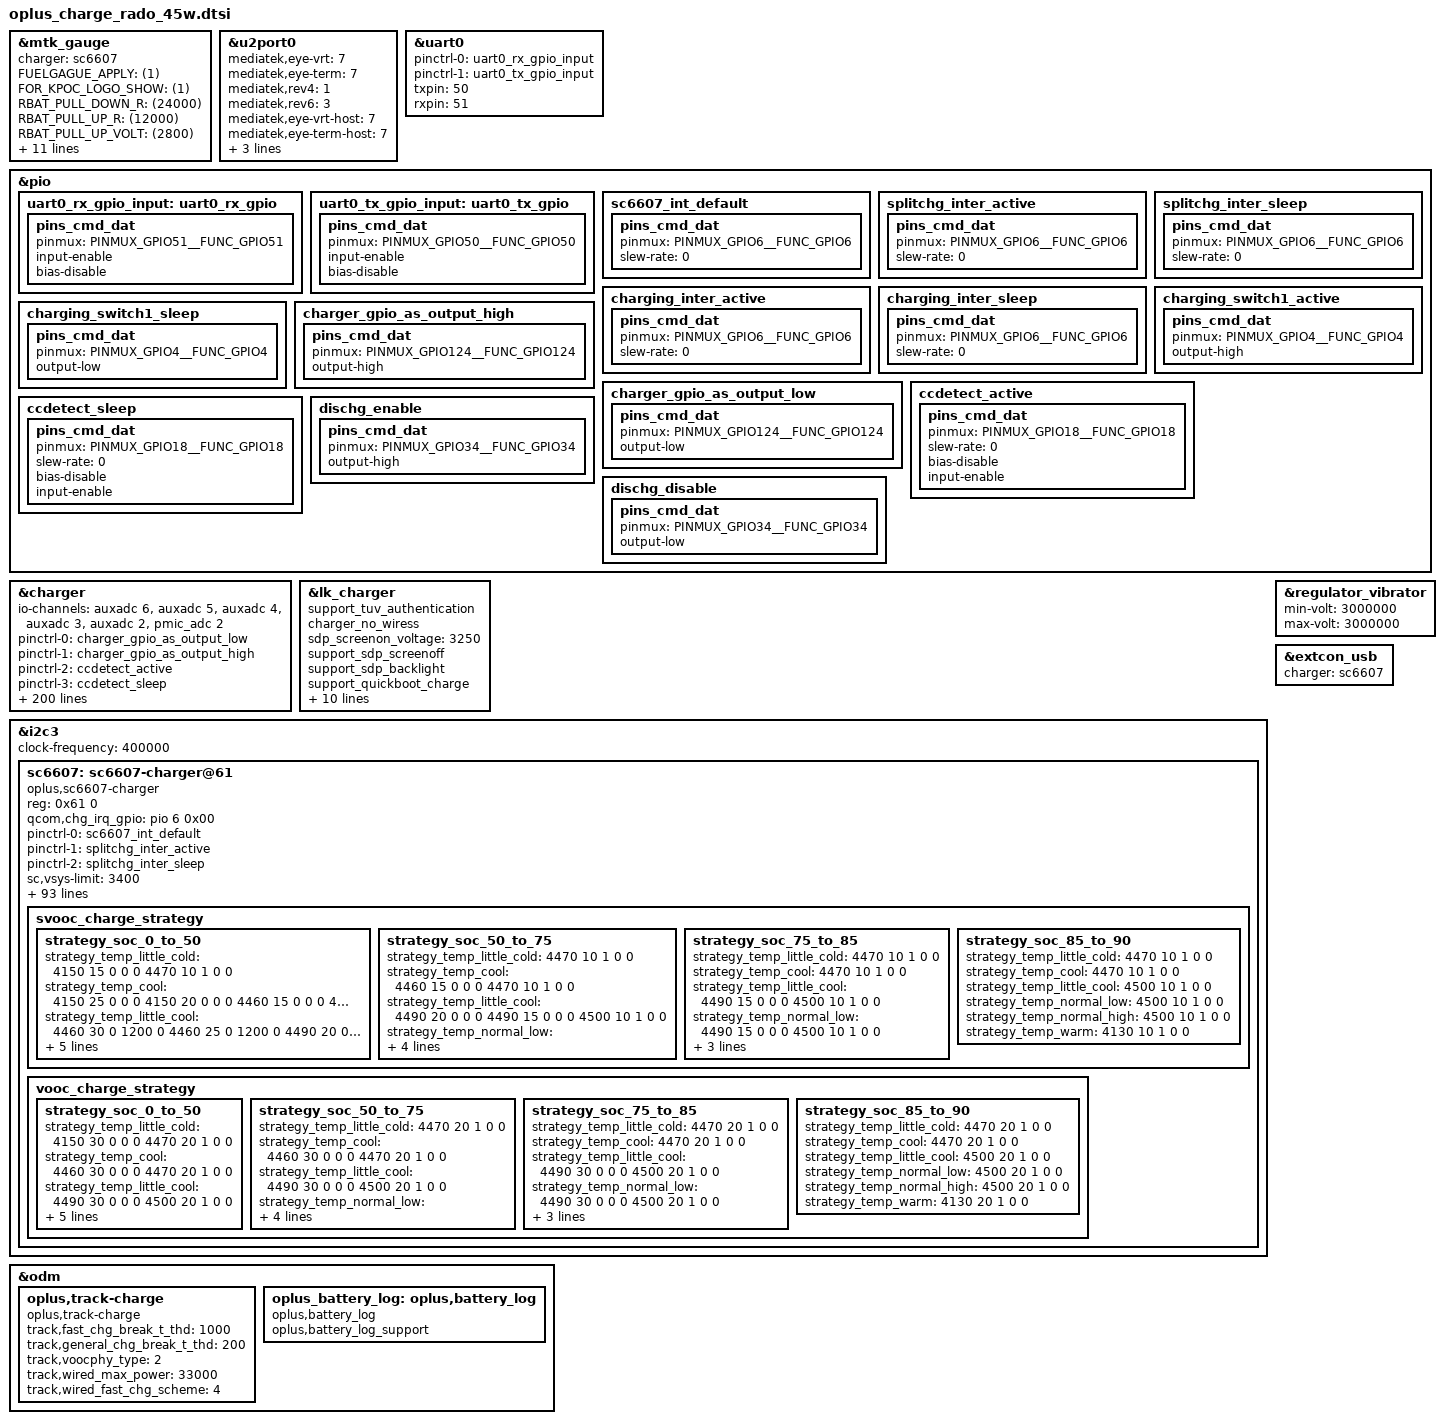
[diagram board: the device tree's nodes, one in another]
// SPDX-License-Identifier: GPL-2.0-only
/*
* Copyright (C) 2021-2020 Oplus. All rights reserved.
*/

/*
 *
 * CPU:MT6835 Barley
 * UTXD0 -->GPIO50
 * URXD0 -->GPIO51
 * I2C
 * MASTER_CHG/CCLOGIC --> I2C5
 * IRQB
 * EINT_CHG_1 (cp1 irq)                -->GPIO6
 * EINT_CHG_2 (cp2 irq)                -->GPIO18
 * CC_CNTL_INT_N(cc login irq)          --> GPIO12
 * CHG_INT(main irq)           --> GPIO3
 *
 * GPIO
 * MAIN/CCLOGIN_SCL               --> GPIO137(SCL5)
 * MAIN/CCLOGIN_SDA               --> GPIO138(SDA5)
 * USB_SWITCH_2(uart/vooc switch)      --> GPIO4
 * VBUS_SHORT(防烧口)           --> GPIO34
 * CHARGER_PUMP1_SCL               --> GPIO133(CP1_SCL3)
 * CHARGER_PUMP1_SDA               --> GPIO134(CP1_SDA3)
 * CHARGER_PUMP2_SCL               --> GPIO141(CP2_SCL7)
 * CHARGER_PUMP2_SDA               --> GPIO142(CP2_SDA7)
 * USB_SWITCH_1(usb/uart&vooc switch)    --> GPIO124
 * SEC_IC (加密电池GPIO for 67W)    --> GPIO44
 *
 * AP_AUXADC:
 * 0				--> FLASH_LED1_NTC
 * 1				--> NTC_USBCON_TEM (BTB VBUS旁)
 * 2				--> NTC_CHARGE (充电IC旁)
 * 3				--> USB_TEM2_ADC (BB_USB_ADC2 r/l?)
 * 4				--> USB_TEM1_ADC (BB_USB_ADC1)
 * 5				--> BAT_ID_ADC   (battery id)
 * 6				--> NTC_charging （BTB电池座子旁）
 */


#include <dt-bindings/iio/mt635x-auxadc.h>
#include <dt-bindings/pinctrl/mt6373-pinfunc.h>
#include <dt-bindings/pinctrl/mt65xx.h>
#include "oplus_chg.h"
/* charge start */

&mtk_gauge {
	status = "okay";
	charger = <&sc6607>;
	FUELGAGUE_APPLY = <(1)>;
	FOR_KPOC_LOGO_SHOW = <(1)>;
	RBAT_PULL_DOWN_R = <(24000)>;
	RBAT_PULL_UP_R = <(12000)>;
	RBAT_PULL_UP_VOLT = <(2800)>;
	USE_MORE_PRECISE_NTC_TABLE = <(1)>;
	//NTC_SERIES_R = <(5100)>;
	FG_METER_RESISTANCE = <(45)>; /* The resistance of PCB */
	CAR_TUNE_VALUE = <(99)>; /* Tune value for current measurement */
	BATT_ID_FAST_CHECK = <(1)>;
	R_FG_VALUE = <(2)>;/* R_sense resistance */
	io-channels = <&pmic_adc AUXADC_BAT_TEMP>,
				<&pmic_adc AUXADC_BATADC>,
				<&pmic_adc AUXADC_VBIF>,
				<&pmic_adc AUXADC_IMP>,
				<&pmic_adc AUXADC_IMIX_R>,
				<&auxadc 5>;
	io-channel-names = "pmic_battery_temp",
					"pmic_battery_voltage",
					"pmic_bif_voltage",
					"pmic_ptim_voltage",
					"pmic_ptim_r",
					 "auxadc5-batt_id_v";


    //IS_SUBBOARD_TEMP_SUPPORT = <(1)>;
	Enable_Is_Force_Full = <(1)>;
	DIM2_TABLE_DISTINGUISH = <(1)>;
	#include "mediatek/bat_setting/mt6835_rado_battery_table_45w.dtsi"
	#include "mediatek/bat_setting/mt6835_rado_battery_prop_dim2_ext_45w.dtsi"
};

&u2port0 {
    mediatek,eye-vrt = <7>;
    mediatek,eye-term = <7>;
    mediatek,rev4 = <1>;
    mediatek,rev6 = <3>;
    mediatek,eye-vrt-host = <7>;
    mediatek,eye-term-host = <7>;
    mediatek,rev6-host = <3>;
    mediatek,discth = <10>;
    mediatek,rx-sqth = <5>;
};


&uart0 {
	pinctrl-names = "uart0_rx_gpio", "uart0_tx_gpio";
	pinctrl-0 = <&uart0_rx_gpio_input>;
	pinctrl-1 = <&uart0_tx_gpio_input>;
	status = "okay";

	txpin = <50>;
	rxpin = <51>;
};

&pio {
	uart0_rx_gpio_input: uart0_rx_gpio {
		pins_cmd_dat {
			pinmux = <PINMUX_GPIO51__FUNC_GPIO51>;
			input-enable;
			bias-disable;
		};
	};

	uart0_tx_gpio_input: uart0_tx_gpio {
		pins_cmd_dat {
			pinmux = <PINMUX_GPIO50__FUNC_GPIO50>;
			input-enable;
			bias-disable;
		};
	};
};


&charger {
	io-channels = <&auxadc 6>,<&auxadc 5>,<&auxadc 4>,<&auxadc 3>,<&auxadc 2>,<&pmic_adc 2>;
	io-channel-names = "auxadc6_batt_btb_temp","auxadc5temp","usb_temp_v_l","usb_temp_v_r","auxadc2-chargeric_temp","pmic_vcdt_voltage";

	pinctrl-names = "charger_gpio_as_output_low","charger_gpio_as_output_high",
					"ccdetect_active","ccdetect_sleep","dischg_enable","dischg_disable";
	pinctrl-0 = <&charger_gpio_as_output_low>;
	pinctrl-1 = <&charger_gpio_as_output_high>;
	pinctrl-2 = <&ccdetect_active>;
	pinctrl-3 = <&ccdetect_sleep>;
	pinctrl-4 = <&dischg_enable>;
	pinctrl-5 = <&dischg_disable>;

	gauge = <&mtk_gauge>;
	charger = <&sc6607>;

	//for oplus chg framework:
	qcom,pps_support_type = <0>;
	qcom,pd_input_current_charger_ma = <2000>;
	qcom,qc_input_current_charger_ma = <2000>;
	qcom,input_current_charger_ma = <2000>;
	qcom,input_current_usb_ma = <500>;
	qcom,input_current_cdp_ma = <1500>;
	qcom,input_current_camera_ma = <1200>;
	qcom,input_current_calling_ma = <1500>;

	qcom,led_warm_bat_decidegc = <350>;
	qcom,led_high_bat_decidegc = <370>;
	qcom,input_current_led_ma = <1200>;
	qcom,input_current_led_ma_high = <1200>;
	qcom,input_current_led_ma_warm = <1500>;
	qcom,input_current_led_ma_normal = <3000>;
	qcom,input_current_led_ma_forcmcc = <500>;
	qcom,input_current_led_ma_limit_high = <1200>;

	qcom,vooc_temp_bat_normal_decidegc = <350>;
	qcom,vooc_temp_bat_warm_decidegc = <370>;
	qcom,vooc_temp_bat_hot_decidegc = <440>;
	qcom,input_current_vooc_led_ma_high = <1200>;
	qcom,input_current_vooc_led_ma_warm = <1800>;
	qcom,input_current_vooc_led_ma_normal = <3600>;
	qcom,input_current_vooc_ma_normal = <3600>;
	qcom,input_current_vooc_ma_warm = <3200>;
	qcom,input_current_vooc_ma_high = <2200>;

	qcom,overtemp_bat_decidegc = <400>;
	qcom,iterm_disabled = <0>;
	//sw_full_count = <25>;
	qcom,iterm_ma = <290>;
	qcom,recharge-mv = <100>;

	qcom,batt_capacity_mah = <5600>; /*typical capacity*/
	qcom,usb_high_than_bat_decidegc = <168>;

	qcom,removed_bat_decidegc = <390>;  /* < -15C */

	qcom,cold_bat_decidegc = <100>;  /* -10C ~ 0C */
	qcom,temp_cold_vfloat_mv = <4465>;
	qcom,temp_cold_fastchg_current_ma_high = <1120>;
	qcom,temp_cold_fastchg_current_ma_low = <840>;
	qcom,temp_cold_fastchg_current_ma = <840>;

	qcom,little_cold_bat_decidegc = <0>;    /* 0C ~ 5C */
	qcom,temp_little_cold_vfloat_mv = <4465>;
	qcom,temp_little_cold_fastchg_current_ma_high = <2200>;
	qcom,temp_little_cold_fastchg_current_ma_low = <2200>;
	qcom,temp_little_cold_fastchg_current_ma = <2200>;
	qcom,qc_temp_little_cold_fastchg_current_ma_high = <3000>;
	qcom,qc_temp_little_cold_fastchg_current_ma_low = <2000>;
	qcom,pd_temp_little_cold_fastchg_current_ma_high = <3000>;
	qcom,pd_temp_little_cold_fastchg_current_ma_low = <2000>;

	qcom,cool_bat_decidegc = <50>;  /* 5C ~ 12C */
	qcom,temp_cool_vfloat_mv = <4465>;
	qcom,temp_cool_fastchg_current_ma_high = <2200>;
	qcom,temp_cool_fastchg_current_ma_low = <2200>;
	qcom,qc_temp_cool_fastchg_current_ma_high = <3000>;
	qcom,qc_temp_cool_fastchg_current_ma_low = <3000>;
	qcom,pd_temp_cool_fastchg_current_ma_high = <3000>;
	qcom,pd_temp_cool_fastchg_current_ma_low = <3000>;

	qcom,little_cool_bat_decidegc = <120>;  /* 12C ~ 16C */
	qcom,temp_little_cool_vfloat_mv = <4465>;
	qcom,temp_little_cool_fastchg_current_ma = <2200>;
	qcom,pd_temp_little_cool_fastchg_current_ma = <3000>;
	qcom,qc_temp_little_cool_fastchg_current_ma = <3000>;

	qcom,normal_bat_decidegc = <160>;       /* 16C ~ 45C */
	qcom,temp_normal_vfloat_mv = <4465>;
	qcom,temp_normal_fastchg_current_ma = <2200>;
	qcom,pd_temp_normal_fastchg_current_ma = <2000>;
	qcom,qc_temp_normal_fastchg_current_ma = <2000>;

	qcom,warm_bat_decidegc = <450>;         /* 45C ~ 53C */ /*8pin Bat Vooc project need add 3 degree C*/
	qcom,temp_warm_vfloat_mv = <4130>;
	qcom,temp_warm_fastchg_current_ma = <2200>;
	qcom,pd_temp_warm_fastchg_current_ma = <2000>;
	qcom,qc_temp_warm_fastchg_current_ma = <2000>;
	qcom,temp_warm_fastchg_current_ma_led_on = <1000>;

	qcom,hot_bat_decidegc = <530>;  /* > 53C */

	qcom,non_standard_vfloat_mv = <3980>;
	qcom,non_standard_fastchg_current_ma = <512>;

	qcom,short_c_bat_cv_mv = <4330>;
	qcom,short_c_bat_vfloat_mv = <3800>;
	qcom,short_c_bat_fastchg_current_ma = <512>;
	qcom,short_c_bat_vfloat_sw_limit = <3750>;

	qcom,cold_vfloat_sw_limit = <4415>;
	qcom,little_cold_vfloat_sw_limit = <4415>;
	qcom,cool_vfloat_sw_limit = <4415>;
	qcom,little_cool_vfloat_sw_limit = <4415>;
	qcom,normal_vfloat_sw_limit = <4415>;
	qcom,warm_vfloat_sw_limit = <4080>;
	qcom,non_standard_vfloat_sw_limit = <3930>;

	qcom,max_chg_time_sec = <72000>;
	qcom,charger_hv_thr = <10000>;
	qcom,charger_recv_thr = <9800>;
	qcom,charger_lv_thr = <3400>;
	qcom,vbatt_full_thr = <4465>;
	qcom,vbatt_hv_thr = <4600>;

	qcom,vfloat_step_mv = <16>;
	qcom,non_standard_vfloat_over_sw_limit = <3990>;
	qcom,cold_vfloat_over_sw_limit = <4445>;
	qcom,little_cold_vfloat_over_sw_limit = <4445>;
	qcom,cool_vfloat_over_sw_limit = <4445>;
	qcom,little_cool_vfloat_over_sw_limit = <4445>;
	qcom,normal_vfloat_over_sw_limit = <4440>;
	qcom,warm_vfloat_over_sw_limit = <4140>;

	qcom,vbatt_power_off = <3300>;
	qcom,vbatt_soc_1 = <3410>;
	qcom,vooc_project = <21>;
	qcom,vbatt_num = <1>;
	qcom,new_ui_warning_support;
	qcom,smart_charging_screenoff;
	qcom,smart_charge_version = <1>;

	qcom,normal_vterm_hw_inc = <18>;
	qcom,non_normal_vterm_hw_inc = <18>;
	qcom,usbtemp_batttemp_gap = <12>;

	qcom,ff1_normal_fastchg_ma = <1500>; /*12C~35c*/
	qcom,ff1_warm_fastchg_ma = <1500>;	/* 35C ~ 40c */
	qcom,ff1_exit_step_ma = <850>;
	qcom,ff1_warm_exit_step_ma = <900>;

	qcom,ffc2_normal_fastchg_ma = <900>;/*12C~35c*/
	qcom,ffc2_warm_fastchg_ma = <1000>;	/* 35C ~ 40c */
	qcom,ffc2_temp_warm_decidegc = <350>;
	qcom,ffc2_temp_high_decidegc = <430>;
	qcom,ffc2_temp_low_decidegc = <120>;
	qcom,ffc2_exit_step_ma = <850>;
	qcom,ffc2_warm_exit_step_ma = <900>;

	qcom,ffc_normal_vfloat_sw_limit = <4495>;
	qcom,ffc_temp_normal_vfloat_mv = <4580>;
	qcom,ffc_normal_vfloat_over_sw_limit = <4630>;
	qcom,ffc_warm_vfloat_sw_limit = <4495>;

	qcom,ffc2_normal_vfloat_sw_limit = <4495>;
	qcom,ffc2_temp_normal_vfloat_mv = <4580>;
	qcom,ffc2_normal_vfloat_over_sw_limit = <4630>;
	qcom,ffc2_warm_vfloat_sw_limit = <4495>;


	qcom,default_iterm_ma = <290>;
	qcom,default_temp_normal_fastchg_current_ma = <2200>;
	qcom,default_normal_vfloat_sw_limit = <4415>;
	qcom,default_temp_normal_vfloat_mv = <4465>;
	qcom,default_normal_vfloat_over_sw_limit = <4475>;

	qcom,default_temp_little_cool_fastchg_current_ma = <2200>;
	qcom,default_little_cool_vfloat_sw_limit = <4415>;
	qcom,default_temp_little_cool_vfloat_mv = <4465>;
	qcom,default_little_cool_vfloat_over_sw_limit = <4475>;

	//for PD9V or QC9V
	qcom,vbatt_pdqc_to_5v_thr = <4500>;
	qcom,vbatt_pdqc_to_9v_thr = <4500>;

	//for PD or QC control
	//qcom,qc_not_support;

	//for control:
	//qcom,suspend_after_full;
	qcom,support_abnormal_adapter;
	qcom,check_batt_full_by_sw;
	qcom,chg_ctrl_by_lcd;
	qcom,chg_ctrl_by_camera;
	qcom,chg_ctrl_by_calling;
	qcom,sw_vfloat_over_protect_enable;
	qcom,usbtemp_dischg_by_platpmic;
	//add for usb temp protect
	qcom,support_usbtemp_protect_v2;
	qcom,usbtemp_batt_temp_low = <50>;
	qcom,usbtemp_batt_temp_high = <50>;
	qcom,usbtemp_ntc_temp_low = <57>;
	qcom,usbtemp_ntc_temp_high = <69>;
	qcom,usbtemp_temp_gap_low_with_batt_temp = <7>;
	qcom,usbtemp_temp_gap_high_with_batt_temp = <12>;
	qcom,usbtemp_temp_gap_low_without_batt_temp = <12>;
	qcom,usbtemp_temp_gap_high_without_batt_temp = <24>;
	qcom.usbtemp_rise_fast_temp_low = <3>;
	qcom.usbtemp_rise_fast_temp_high = <3>;
	qcom.usbtemp_rise_fast_temp_count_low = <30>;
	qcom.usbtemp_rise_fast_temp_count_high = <20>;

	qcom,usbtemp_cool_down_ntc_low = <54>;
	qcom,usbtemp_cool_down_ntc_high = <65>;
	qcom,usbtemp_cool_down_gap_low = <12>;
	qcom,usbtemp_cool_down_gap_high = <20>;
	qcom,usbtemp_cool_down_recover_ntc_low = <48>;
	qcom,usbtemp_cool_down_recover_ntc_high = <60>;
	qcom,usbtemp_cool_down_recover_gap_low = <6>;
	qcom,usbtemp_cool_down_recover_gap_high = <15>;
	qcom,ffc_support;
	qcom,chargerid_vol_disable;
	qcom,support_ntc_01c_precision;
	qcom,voocphy_support = <2>;
	//qcom,external_authenticate;
	qcom,chargerid_support;
	qcom,vooc_show_ui_soc_decimal;
	qcom,ui_soc_decimal_speedmin = <20>;//2A
	//qcom,ccdetect_by_wd0;
	qcom,hvdcp_disabled; //do'not supprot hvdcp
	//GPIO config:
	qcom,chargerid_switch-gpio = <&pio 124 0x00>;/*USB_SWITCH_1*/
	qcom,dischg-gpio = <&pio 34 0x00>;/*VBUS_SHORT*/
	qcom,ccdetect-gpio = <&pio 18 0x00>;

	qcom,vooc-max-input-volt-support = <10000>;     //10V
	qcom,vooc-max-input-current-support = <3000>;   //3A

	oplus,uart_tx-gpio = <&pio 50 0x00>;
	oplus,uart_rx-gpio = <&pio 51 0x00>;
};

&lk_charger {
	support_tuv_authentication;
	charger_no_wiress;
	sdp_screenon_voltage = <3250>;
	//sub_board_temp_support;
	support_sdp_screenoff;
	support_sdp_backlight;
	support_quickboot_charge;
	support_4p48_single_battery;
	max_charger_voltage = <15000000>;
	boot_battery_voltage = <3400000>;
	usb_charger_current = <500000>;
	ac_charger_current = <2050000>;
	ac_charger_input_current = <1500000>;
	non_std_ac_charger_current = <750000>;
	charging_host_charger_current = <1500000>;
	ta_ac_charger_current = <1500000>;
	pd_charger_current = <500000>;
};

&i2c3 {
	status = "okay";
	clock-frequency = <400000>;//400K
	sc6607:sc6607-charger@61{
		status = "okay";
		compatible = "oplus,sc6607-charger";
		reg = <0x61 0>;

		qcom,chg_irq_gpio = <&pio 6 0x00>;
		pinctrl-names = "default",
				"splitchg_inter_active",
				"splitchg_inter_sleep";

		pinctrl-0 = <&sc6607_int_default>;
		pinctrl-1 = <&splitchg_inter_active>;
		pinctrl-2 = <&splitchg_inter_sleep>;
		sc,vsys-limit = <3400>;
		sc,vbat = <4450>;
		sc,charge-curr = <2000>;
		sc,iindpm-disable = <0>;
		sc,input-curr-limit = <500>;
		sc,ico-enable = <0>;
		sc,precharge-volt = <0>;      /* 0:2700mv , 1:3000mv */
		sc,precharge-curr = <500>;
		sc,term-en = <1>;
		sc,term-curr = <100>;     /* ma */
		sc,rechg-dis = <1>;
		sc,boost-voltage = <5000>;
		sc,boost-max-current = <1300>;
		sc,conv-ocp-dis = <0>;
		sc,tsbat-jeita-dis = <1>;
		sc,vpmid-ovp-otg-dis = <0>;
		sc,vbat-ovp-buck-dis = <0>;
		sc,ibat-ocp = <1>;    /* 0:12A , 1:16A */
		ocp_reg = <0xf>;    /* 4.75A*/
		ovp_reg = <0x36>;	/* 4.85V */
		sc,charge-detect-enable;
		/*
		 * Charger name
		 * Main charger: primary_chg
		 * Slave charger: secondary_chg
		 */
		charger_name = "primary_chg";
		qcom,copycat_vooc_support;
		oplus,copycat_identify_algorithm = <2>;
		oplus,copycat-vooc-count = <4>;
		oplus,workaround_for_100w;
		qcom,voocphy_current_default = <61>;/*6100mA*/
		qcom,svooc_cool_down_current_limit = <82 20 20 24 30 34 40 44 50 54 82>;
		qcom,vooc_cool_down_current_limit = <30 20 20 24 30>;
		qcom,abnormal_adapter_current = <60 60 40 40>;
		qcom,vooc_little_cold_full_voltage = <4470>;
		qcom,vooc_cool_full_voltage = <4470>;
		qcom,vooc_warm_full_voltage = <4130>;
		qcom,vooc_1time_full_voltage = <4510>;
		qcom,vooc_ntime_full_voltage = <4500>;
		qcom,low_curr_full_t1 = <120>;
		qcom,low_curr_full_t2 = <350>;
		qcom,low_curr_full_t3 = <430>;
		qcom,range1_low_curr_full = <850 4500
						750 4495
						650 4480
						550 4470
						450 4460>;
		qcom,range2_low_curr_full = <950 4500
						850 4495
						750 4480
						650 4470
						550 4460>;

		qcom,vooc_multistep_initial_batt_temp = <1000>;
		qcom,vooc_little_cool_temp = <200>;
		qcom,vooc_cool_temp = <120>;
		qcom,vooc_little_cold_temp = <50>;
		qcom,vooc_normal_low_temp = <350>;
		qcom,vooc_strategy_normal_current = <100>;
		qcom,vooc_normal_to_little_cool_current = <100>;
		qcom,vooc_batt_over_high_temp = <510>;
		qcom,vooc-low-temp = <0>;
		qcom,vooc-high-temp = <500>;
		qcom,vooc-low-soc = <0>;
		qcom,vooc-high-soc = <90>;
		qcom,vooc-normal-high-temp = <440>;
		qcom,vooc-warm-allow-vol = <4000>;
		qcom,vooc-warm-allow-soc = <50>;
		qcom,impedance_calculation_newmethod;
		qcom,svooc_circuit_r_l = <0x18>;
		qcom,svooc_circuit_r_h = <0x2>;/* 65 mR */

		qcom,vooc_strategy1_batt_high_temp0 = <400>;
		qcom,vooc_strategy1_batt_high_temp1 = <420>;
		qcom,vooc_strategy1_batt_high_temp2 = <430>;
		qcom,vooc_strategy1_batt_low_temp2 = <420>;
		qcom,vooc_strategy1_batt_low_temp1 = <410>;
		qcom,vooc_strategy1_batt_low_temp0 = <390>;

		qcom,vooc_strategy1_high_current0 = <50>;
		qcom,vooc_strategy1_high_current1 = <40>;
		qcom,vooc_strategy1_high_current2 = <20>;
		qcom,vooc_strategy1_low_current2 = <40>;
		qcom,vooc_strategy1_low_current1 = <50>;
		qcom,vooc_strategy1_low_current0 = <60>;

		qcom,vooc_strategy1_high_current0_vooc = <20>;
		qcom,vooc_strategy1_high_current1_vooc = <20>;
		qcom,vooc_strategy1_high_current2_vooc = <20>;
		qcom,vooc_strategy1_low_current2_vooc = <30>;
		qcom,vooc_strategy1_low_current1_vooc = <30>;
		qcom,vooc_strategy1_low_current0_vooc = <30>;

		qcom,voocphy_ibat_over_current = <8500>;
		qcom,voocphy_cp_max_ibus = <4750>;
		qcom,voocphy_svooc_cp_max_ibus = <4750>;
		qcom,voocphy_vooc_cp_max_ibus = <3500>;
		qcom,batt_pwd_curr_thd1 = <4300>;
		qcom,batt_pwd_vol_thd1 = <4514>;

		qcom,voocphy_freq_mincore = <999000>;
		qcom,voocphy_freq_midcore = <1443000>;
		qcom,voocphy_freq_maxcore = <1443000>;
		qcom,voocphy_current_change_timeout = <100>;

		svooc_batt_sys_curve = <0 1 0 1 0 0 1	// 4100mA
					0 0 0 0 0 0 1	// 3414mV
					0 0 1 0 1 0 0	// 2000mA
					1 1 1 1 1 1 0	// 4664mV
					0 0 0 1 0 1 0	// 1000mA
					1 1 1 1 1 1 0>;	// 4664mV

		vooc_batt_sys_curve =  <0 0 1 1 1 1 0	// 3000mA
					0 0 0 0 0 0 1	// 3414mV
					0 0 1 0 1 0 0	// 2000mA
					1 1 1 1 1 1 0	// 4664mV
					0 0 0 1 0 1 0	// 1000mA
					1 1 1 1 1 1 0>;	// 4664mV

	    	svooc_charge_strategy {
			strategy_soc_0_to_50 {
				strategy_temp_little_cold =	<4150 15 0 0 0
								 4470 10 1 0 0>;
				strategy_temp_cool =		<4150 25 0 0 0
								 4150 20 0 0 0
								 4460 15 0 0 0
								 4470 10 1 0 0>;
				strategy_temp_little_cool =	<4460 30 0 1200 0
								 4460 25 0 1200 0
								 4490 20 0 0 0
								 4490 15 0 0 0
								 4500 10 1 0 0>;
				strategy_temp_normal_low =	<4230 41 0 60 0
								 4460 30 0 1200 0 //min*60*1000/500
								 4460 25 0 1200 0 //min*60*1000/500
								 4490 20 0 0 0
								 4490 15 0 0 0
								 4500 10 1 0 0>;
				strategy_temp_normal_high =	<4230 41 0 60 0
								 4460 30 0 1200 0 //min*60*1000/500
								 4460 25 0 1200 0 //min*60*1000/500
								 4490 20 0 0 0
								 4490 15 0 0 0
								 4500 10 1 0 0>;
				strategy_temp_warm = 		<4130 10 1 0 0>;
			};

			strategy_soc_50_to_75 {
				strategy_temp_little_cold =	<4470 10 1 0 0>;
				strategy_temp_cool =		<4460 15 0 0 0
								 4470 10 1 0 0>;
				strategy_temp_little_cool =	<4490 20 0 0 0
								 4490 15 0 0 0
								 4500 10 1 0 0>;
				strategy_temp_normal_low =	<4460 25 0 0 0
								 4490 20 0 0 0
								 4490 15 0 0 0
								 4500 10 1 0 0>;
				strategy_temp_normal_high =	<4460 25 0 0 0
								 4490 20 0 0 0
								 4490 15 0 0 0
								 4500 10 1 0 0>;
				strategy_temp_warm =		<4130 10 1 0 0>;
			};

			strategy_soc_75_to_85 {
				strategy_temp_little_cold =	<4470 10 1 0 0>;
				strategy_temp_cool =		<4470 10 1 0 0>;
				strategy_temp_little_cool =	<4490 15 0 0 0
								 4500 10 1 0 0>;
				strategy_temp_normal_low =	<4490 15 0 0 0
								 4500 10 1 0 0>;
				strategy_temp_normal_high =	<4490 15 0 0 0
								 4500 10 1 0 0>;
				strategy_temp_warm =		<4130 10 1 0 0>;
			};

			strategy_soc_85_to_90 {
				strategy_temp_little_cold =	<4470 10 1 0 0>;
				strategy_temp_cool =		<4470 10 1 0 0>;
				strategy_temp_little_cool =	<4500 10 1 0 0>;
				strategy_temp_normal_low =	<4500 10 1 0 0>;
				strategy_temp_normal_high =	<4500 10 1 0 0>;
				strategy_temp_warm =		<4130 10 1 0 0>;
			};
		};

		vooc_charge_strategy {
			strategy_soc_0_to_50 {
				strategy_temp_little_cold =	<4150 30 0 0 0
								 4470 20 1 0 0>; /*0-5C*/
				strategy_temp_cool =		<4460 30 0 0 0
								 4470 20 1 0 0>; /*5-12C*/
				strategy_temp_little_cool =	<4490 30 0 0 0
								 4500 20 1 0 0>; /*12-16C*/
				strategy_temp_normal_low =	<4490 30 0 0 0
								 4500 20 1 0 0>; /*16-25C*/
				strategy_temp_normal_high =	<4490 30 0 0 0
								 4500 20 1 0 0>; /*25-44CC*/
				strategy_temp_warm = 		<4130 20 1 0 0>;
			};

			strategy_soc_50_to_75 {
				strategy_temp_little_cold =	<4470 20 1 0 0>;
				strategy_temp_cool =		<4460 30 0 0 0
								 4470 20 1 0 0>;
				strategy_temp_little_cool =	<4490 30 0 0 0
								 4500 20 1 0 0>;
				strategy_temp_normal_low =	<4490 30 0 0 0
								 4500 20 1 0 0>;
				strategy_temp_normal_high =	<4490 30 0 0 0
								 4500 20 1 0 0>;
				strategy_temp_warm = 		<4130 20 1 0 0>;
			};

			strategy_soc_75_to_85 {
				strategy_temp_little_cold =	<4470 20 1 0 0>;
				strategy_temp_cool =		<4470 20 1 0 0>;
				strategy_temp_little_cool =	<4490 30 0 0 0
								 4500 20 1 0 0>;
				strategy_temp_normal_low =	<4490 30 0 0 0
								 4500 20 1 0 0>;
				strategy_temp_normal_high =	<4490 30 0 0 0
								 4500 20 1 0 0>;
				strategy_temp_warm = 		<4130 20 1 0 0>;
			};

			strategy_soc_85_to_90 {
				strategy_temp_little_cold =	<4470 20 1 0 0>;
				strategy_temp_cool =		<4470 20 1 0 0>;
				strategy_temp_little_cool =	<4500 20 1 0 0>;
				strategy_temp_normal_low =	<4500 20 1 0 0>;
				strategy_temp_normal_high =	<4500 20 1 0 0>;
				strategy_temp_warm = 		<4130 20 1 0 0>;
			};
		};
	};
};

&pio {
	sc6607_int_default: sc6607_int_default {
		pins_cmd_dat {
			pinmux = <PINMUX_GPIO6__FUNC_GPIO6>;
			slew-rate = <0>;
		};
	};
	/*split_chg*/
	splitchg_inter_active: splitchg_inter_active {
		pins_cmd_dat {
			pinmux = <PINMUX_GPIO6__FUNC_GPIO6>;
			slew-rate = <0>;
		};
	};

	splitchg_inter_sleep: splitchg_inter_sleep {
		pins_cmd_dat {
			pinmux = <PINMUX_GPIO6__FUNC_GPIO6>;
			slew-rate = <0>;
		};
	};
};

/*&i2c7 {
	status = "okay";
	sc8547-charger-slave@6F{
		status = "disabled";
		compatible = "sc,sc8547-slave";
		reg = <0x6F 0>;
	};
};*/

&pio {
/*CP1 EINT*/
	charging_inter_active: charging_inter_active {
		pins_cmd_dat {
			pinmux = <PINMUX_GPIO6__FUNC_GPIO6>;
			slew-rate = <0>;
		};
	};

	charging_inter_sleep: charging_inter_sleep {
		pins_cmd_dat {
			pinmux = <PINMUX_GPIO6__FUNC_GPIO6>;
			slew-rate = <0>;
		};
	};
/*usb_switch_2, for uart/vooc*/
	charging_switch1_active: charging_switch1_active {
		pins_cmd_dat {
			pinmux = <PINMUX_GPIO4__FUNC_GPIO4>;
			output-high;
		};
	};

	charging_switch1_sleep: charging_switch1_sleep {
		pins_cmd_dat {
			pinmux = <PINMUX_GPIO4__FUNC_GPIO4>;
			output-low;
		};
	};
/*usb_switch_1, for usb/uart&vooc*/
	charger_gpio_as_output_high: charger_gpio_as_output_high {
		pins_cmd_dat {
			pinmux = <PINMUX_GPIO124__FUNC_GPIO124>;
			output-high;
		};
	};
	charger_gpio_as_output_low: charger_gpio_as_output_low {
		pins_cmd_dat {
			pinmux = <PINMUX_GPIO124__FUNC_GPIO124>;
			output-low;
		};
	};
/*CC_INTB*/
	ccdetect_active: ccdetect_active {
		pins_cmd_dat {
			pinmux = <PINMUX_GPIO18__FUNC_GPIO18>;
			slew-rate = <0>;
			bias-disable;
			input-enable;
		};
	};
	ccdetect_sleep: ccdetect_sleep {
		pins_cmd_dat {
			pinmux = <PINMUX_GPIO18__FUNC_GPIO18>;
			slew-rate = <0>;
			bias-disable;
			input-enable;
		};
	};
/*VBUS_SHORT*/
	dischg_enable: dischg_enable {
		pins_cmd_dat {
			pinmux = <PINMUX_GPIO34__FUNC_GPIO34>;
			output-high;
		};
	};
	dischg_disable: dischg_disable {
		pins_cmd_dat {
			pinmux = <PINMUX_GPIO34__FUNC_GPIO34>;
			output-low;
		};
	};
};

&regulator_vibrator{
	min-volt = <3000000>;
	max-volt = <3000000>;
};

&extcon_usb {
	charger = <&sc6607>;
	status = "okay";
};

/*&charger {
	charger = <&sgm41542>;
	status = "okay";
};*/

/*&sgm7220_typec {
	charger = <&sgm41542>;
	status = "okay";
};*/

&odm {
	oplus,track-charge {
		compatible = "oplus,track-charge";
		track,fast_chg_break_t_thd = <1000>;
		track,general_chg_break_t_thd = <200>;
		track,voocphy_type = <2>;
		track,wired_max_power = <33000>;
		track,wired_fast_chg_scheme = <4>;
	};

	oplus_battery_log: oplus,battery_log {
		compatible = "oplus,battery_log";
		oplus,battery_log_support;
	};
};

/* chagrge end */
